# TM4C123GH6PGE register map
Vendor: Texas Instruments; File version: 11073
CPU: CM4 r1p2, little endian, no MPU, no FPU, 0x3 interrupt priority bits, 0x0 interrupts
Registers are 32-bit, read-write, no defined reset value unless marked. A register's access mark holds for its fields unless they carry their own. Offsets are from the block's base; [hi:lo] are bit positions; {n}, {i} and the like mark numbered series.

## QEI0 — Register map for QEI0 peripheral
Base 0x4002C000; register names take the prefix QEI0
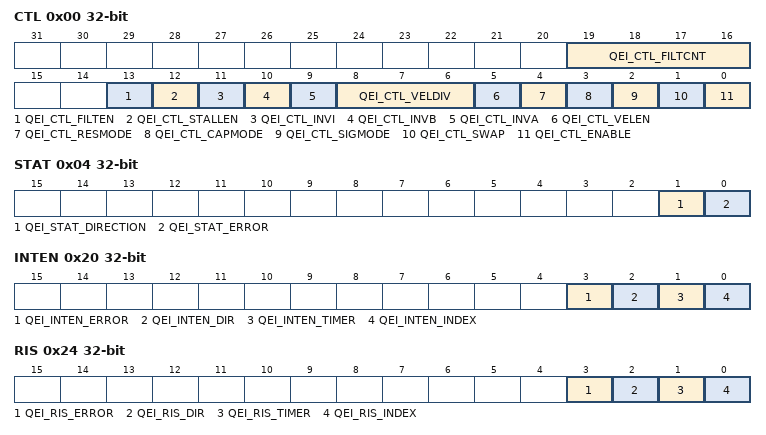
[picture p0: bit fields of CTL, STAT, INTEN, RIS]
0x00 CTL — QEI Control
  [19:16] QEI_CTL_FILTCNT — Input Filter Prescale Count
  [13] QEI_CTL_FILTEN — Enable Input Filter
  [12] QEI_CTL_STALLEN — Stall QEI
  [11] QEI_CTL_INVI — Invert Index Pulse
  [10] QEI_CTL_INVB — Invert PhB
  [9] QEI_CTL_INVA — Invert PhA
  [8:6] QEI_CTL_VELDIV — Predivide Velocity
    0=QEI clock /1; 1=QEI clock /2; 2=QEI clock /4; 3=QEI clock /8; 4=QEI clock /16; 5=QEI clock /32; 6=QEI clock /64; 7=QEI clock /128
  [5] QEI_CTL_VELEN — Capture Velocity
  [4] QEI_CTL_RESMODE — Reset Mode
  [3] QEI_CTL_CAPMODE — Capture Mode
  [2] QEI_CTL_SIGMODE — Signal Mode
  [1] QEI_CTL_SWAP — Swap Signals
  [0] QEI_CTL_ENABLE — Enable QEI
0x04 STAT — QEI Status
  [1] QEI_STAT_DIRECTION — Direction of Rotation
  [0] QEI_STAT_ERROR — Error Detected
0x08 POS — QEI Position
  [31:0] QEI_POS — Current Position Integrator Value
0x0C MAXPOS — QEI Maximum Position
  [31:0] QEI_MAXPOS — Maximum Position Integrator Value
0x10 LOAD — QEI Timer Load
  [31:0] QEI_LOAD — Velocity Timer Load Value
0x14 TIME — QEI Timer
  [31:0] QEI_TIME — Velocity Timer Current Value
0x18 COUNT — QEI Velocity Counter
  [31:0] QEI_COUNT — Velocity Pulse Count
0x1C SPEED — QEI Velocity
  [31:0] QEI_SPEED — Velocity
0x20 INTEN — QEI Interrupt Enable
  [3] QEI_INTEN_ERROR — Phase Error Interrupt Enable
  [2] QEI_INTEN_DIR — Direction Change Interrupt Enable
  [1] QEI_INTEN_TIMER — Timer Expires Interrupt Enable
  [0] QEI_INTEN_INDEX — Index Pulse Detected Interrupt Enable
0x24 RIS — QEI Raw Interrupt Status
  [3] QEI_RIS_ERROR — Phase Error Detected
  [2] QEI_RIS_DIR — Direction Change Detected
  [1] QEI_RIS_TIMER — Velocity Timer Expired
  [0] QEI_RIS_INDEX — Index Pulse Asserted
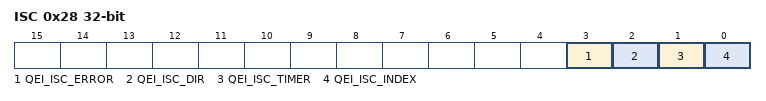
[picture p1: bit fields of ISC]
0x28 ISC — QEI Interrupt Status and Clear
  [3] QEI_ISC_ERROR — Phase Error Interrupt
  [2] QEI_ISC_DIR — Direction Change Interrupt
  [1] QEI_ISC_TIMER — Velocity Timer Expired Interrupt
  [0] QEI_ISC_INDEX — Index Pulse Interrupt

## QEI1 — Register map for QEI0 peripheral
Base 0x4002D000; register names take the prefix QEI1
Registers as QEI0.

## EEPROM — Register map for EEPROM peripheral
Base 0x400AF000; register names take the prefix EEPROM
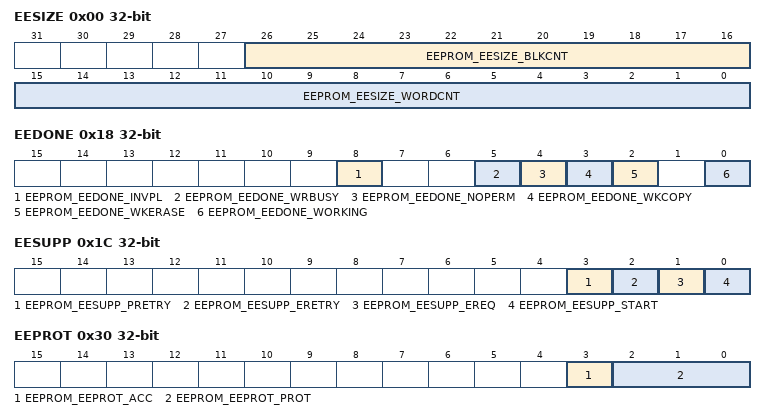
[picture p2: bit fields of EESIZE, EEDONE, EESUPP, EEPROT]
0x00 EESIZE — EEPROM Size Information
  [26:16] EEPROM_EESIZE_BLKCNT — Number of 16-Word Blocks
  [15:0] EEPROM_EESIZE_WORDCNT — Number of 32-Bit Words
0x04 EEBLOCK — EEPROM Current Block
  [15:0] EEPROM_EEBLOCK_BLOCK — Current Block
0x08 EEOFFSET — EEPROM Current Offset
  [3:0] EEPROM_EEOFFSET_OFFSET — Current Address Offset
0x10 EERDWR — EEPROM Read-Write
  [31:0] EEPROM_EERDWR_VALUE — EEPROM Read or Write Data
0x14 EERDWRINC — EEPROM Read-Write with Increment
  [31:0] EEPROM_EERDWRINC_VALUE — EEPROM Read or Write Data with Increment
0x18 EEDONE — EEPROM Done Status
  [8] EEPROM_EEDONE_INVPL — Invalid Program Voltage Level
  [5] EEPROM_EEDONE_WRBUSY — Write Busy
  [4] EEPROM_EEDONE_NOPERM — Write Without Permission
  [3] EEPROM_EEDONE_WKCOPY — Working on a Copy
  [2] EEPROM_EEDONE_WKERASE — Working on an Erase
  [0] EEPROM_EEDONE_WORKING — EEPROM Working
0x1C EESUPP — EEPROM Support Control and Status
  [3] EEPROM_EESUPP_PRETRY — Programming Must Be Retried
  [2] EEPROM_EESUPP_ERETRY — Erase Must Be Retried
  [1] EEPROM_EESUPP_EREQ — Erase Required
  [0] EEPROM_EESUPP_START — Start Erase
0x20 EEUNLOCK — EEPROM Unlock
  [31:0] EEPROM_EEUNLOCK_UNLOCK
0x30 EEPROT — EEPROM Protection
  [3] EEPROM_EEPROT_ACC — Access Control
  [2:0] EEPROM_EEPROT_PROT — Protection Control
    0=EEPROM_EEPROT_PROT_RWNPW (This setting is the default. If there is no password, the block is not protected and is readable and writable); 1=EEPROM_EEPROT_PROT_RWPW (If there is a password, the block is readable or writable only when unlocked); 2=EEPROM_EEPROT_PROT_RONPW (If there is no password, the block is readable, not writable)
{0x34+4i} EEPASS{i} (i=0..2) — EEPROM Password
  [31:0] EEPROM_EEPASS{i}_PASS — Password
0x40 EEINT — EEPROM Interrupt
  [0] EEPROM_EEINT_INT — Interrupt Enable
0x50 EEHIDE — EEPROM Block Hide
  [31:1] EEPROM_EEHIDE_HN — Hide Block
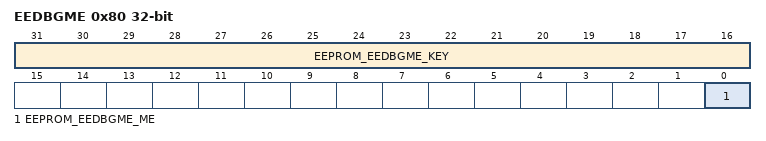
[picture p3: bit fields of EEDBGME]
0x80 EEDBGME — EEPROM Debug Mass Erase
  [31:16] EEPROM_EEDBGME_KEY — Erase Key
  [0] EEPROM_EEDBGME_ME — Mass Erase
0xFC0 PP — EEPROM Peripheral Properties
  [4:0] EEPROM_PP_SIZE — EEPROM Size
